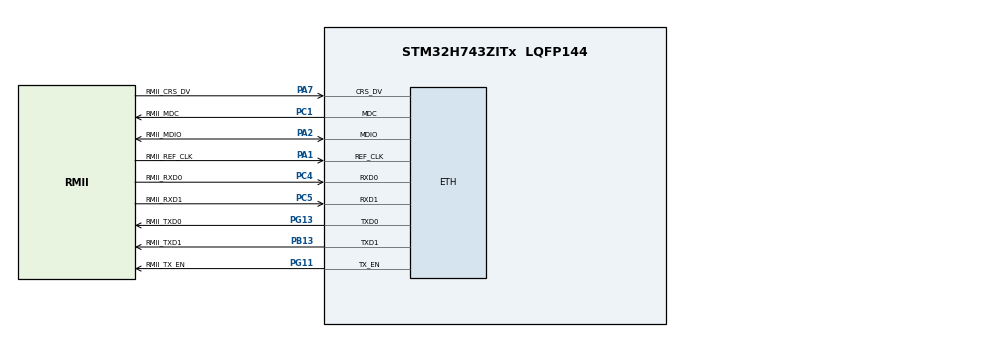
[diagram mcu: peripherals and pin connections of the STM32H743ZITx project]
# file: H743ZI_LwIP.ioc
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CORTEX_M7.AccessPermission-Cortex_Memory_Protection_Unit_Region0_Settings=MPU_REGION_FULL_ACCESS
CORTEX_M7.BaseAddress-Cortex_Memory_Protection_Unit_Region0_Settings=0x30040000
CORTEX_M7.BaseAddress-Cortex_Memory_Protection_Unit_Region1_Settings=0x30044000
CORTEX_M7.CPU_DCache=Enabled
CORTEX_M7.CPU_ICache=Enabled
CORTEX_M7.Enable-Cortex_Memory_Protection_Unit_Region0_Settings=MPU_REGION_ENABLE
CORTEX_M7.Enable-Cortex_Memory_Protection_Unit_Region1_Settings=MPU_REGION_ENABLE
CORTEX_M7.IsBufferable-Cortex_Memory_Protection_Unit_Region0_Settings=MPU_ACCESS_BUFFERABLE
CORTEX_M7.IsCacheable-Cortex_Memory_Protection_Unit_Region1_Settings=MPU_ACCESS_CACHEABLE
CORTEX_M7.MPU_Control=MPU_PRIVILEGED_DEFAULT
CORTEX_M7.Size-Cortex_Memory_Protection_Unit_Region0_Settings=MPU_REGION_SIZE_256B
CORTEX_M7.Size-Cortex_Memory_Protection_Unit_Region1_Settings=MPU_REGION_SIZE_16KB
ETH.MediaInterface=HAL_ETH_RMII_MODE
LWIP.BSP.number=1
LWIP.GATEWAY_ADDRESS=192.168.001.001
LWIP.IP_ADDRESS=192.168.001.100
LWIP.LWIP_DHCP=0
LWIP.NETMASK_ADDRESS=255.255.255.000
LWIP.Version=v2.0.3_Cube
LWIP0.BSP.STBoard=false
LWIP0.BSP.api=BSP_COMPONENT_DRIVER
LWIP0.BSP.component=LAN8742
LWIP0.BSP.i2caddr=0
LWIP0.BSP.instance=LAN8742
LWIP0.BSP.name=Driver_PHY
LWIP0.BSP.solution=LAN8742
Mcu.Family=STM32H7
Mcu.Name=STM32H743ZITx
Mcu.Package=LQFP144
NVIC.PriorityGroup=NVIC_PRIORITYGROUP_4
PA1.GPIO_Label=RMII_REF_CLK
PA1.GPIO_Speed=GPIO_SPEED_FREQ_HIGH
PA1.Mode=RMII
PA1.Signal=ETH_REF_CLK
PA13\ (JTMS/SWDIO).GPIO_Label=TMS
PA13\ (JTMS/SWDIO).Mode=Serial_Wire
PA13\ (JTMS/SWDIO).Signal=SYS_JTMS-SWDIO
PA14\ (JTCK/SWCLK).GPIO_Label=TCK
PA14\ (JTCK/SWCLK).Mode=Serial_Wire
PA14\ (JTCK/SWCLK).Signal=SYS_JTCK-SWCLK
PA2.GPIO_Label=RMII_MDIO
PA2.GPIO_Speed=GPIO_SPEED_FREQ_HIGH
PA2.Mode=RMII
PA2.Signal=ETH_MDIO
PA7.GPIO_Label=RMII_CRS_DV
PA7.GPIO_Speed=GPIO_SPEED_FREQ_HIGH
PA7.Mode=RMII
PA7.Signal=ETH_CRS_DV
PB13.GPIO_Label=RMII_TXD1
PB13.GPIO_Speed=GPIO_SPEED_FREQ_HIGH
PB13.Mode=RMII
PB13.Signal=ETH_TXD1
PC1.GPIO_Label=RMII_MDC
PC1.Mode=RMII
PC1.Signal=ETH_MDC
PC4.GPIO_Label=RMII_RXD0
PC4.GPIO_Speed=GPIO_SPEED_FREQ_HIGH
PC4.Mode=RMII
PC4.Signal=ETH_RXD0
PC5.GPIO_Label=RMII_RXD1
PC5.GPIO_Speed=GPIO_SPEED_FREQ_HIGH
PC5.Mode=RMII
PC5.Signal=ETH_RXD1
PG11.GPIO_Label=RMII_TX_EN
PG11.GPIO_Speed=GPIO_SPEED_FREQ_HIGH
PG11.Mode=RMII
PG11.Signal=ETH_TX_EN
PG13.GPIO_Label=RMII_TXD0
PG13.GPIO_Speed=GPIO_SPEED_FREQ_HIGH
PG13.Mode=RMII
PG13.Signal=ETH_TXD0
PH0-OSC_IN\ (PH0).GPIO_Label=MCO
PH0-OSC_IN\ (PH0).Mode=HSE-External-Oscillator
PH0-OSC_IN\ (PH0).Signal=RCC_OSC_IN
PH1-OSC_OUT\ (PH1).Mode=HSE-External-Oscillator
PH1-OSC_OUT\ (PH1).Signal=RCC_OSC_OUT
ProjectManager.HeapSize=0x2000
ProjectManager.StackSize=0x4000
ProjectManager.TargetToolchain=Makefile
RCC.48MHZClocksFreq_Value=24000000
RCC.ADCFreq_Value=16125000
RCC.AHBFreq_Value=216000000
RCC.APB1CLKDivider=RCC_HCLK_DIV4
RCC.APB1Freq_Value=100000000
RCC.APB1TimFreq_Value=108000000
RCC.APB2CLKDivider=RCC_HCLK_DIV2
RCC.APB2Freq_Value=100000000
RCC.APB2TimFreq_Value=216000000
RCC.APB3Freq_Value=100000000
RCC.APB4Freq_Value=100000000
RCC.CortexFreq_Value=400000000
RCC.D1PPRE=RCC_APB3_DIV2
RCC.D2PPRE1=RCC_APB1_DIV2
RCC.D2PPRE2=RCC_APB2_DIV2
RCC.D3PPRE=RCC_APB4_DIV2
RCC.DIVM1=1
RCC.DIVN1=100
RCC.DIVQ1=4
RCC.HCLKFreq_Value=200000000
RCC.HPRE=RCC_HCLK_DIV2
RCC.HSE_VALUE=8000000
RCC.HSI_VALUE=64000000
RCC.PLLM=25
RCC.PLLMUL=RCC_PLL_MUL9
RCC.PLLN=432
RCC.PLLQ=9
RCC.PLLSourceVirtual=RCC_PLLSOURCE_HSE
RCC.PRESCALERUSB=RCC_USBCLKSOURCE_PLL_DIV1_5
RCC.SYSCLKFreq_VALUE=400000000
RCC.SYSCLKSource=RCC_SYSCLKSOURCE_PLLCLK
RCC.SYSCLKSourceVirtual=RCC_SYSCLKSOURCE_PLLCLK
RCC.USBFreq_Value=200000000
RCC.VCOOutputFreq_Value=432000000
VP_LWIP_VS_Enabled.Mode=Enabled
board=NUCLEO-H743ZI

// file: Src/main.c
/* USER CODE BEGIN Header */
/**
  ******************************************************************************
  * @file           : main.c
  * @brief          : Main program body
  ******************************************************************************
  * This notice applies to any and all portions of this file
  * that are not between comment pairs USER CODE BEGIN and
  * USER CODE END. Other portions of this file, whether
  * inserted by the user or by software development tools
  * are owned by their respective copyright owners.
  *
  * Copyright (c) 2019 STMicroelectronics International N.V.
  * All rights reserved.
  *
  * Redistribution and use in source and binary forms, with or without
  * modification, are permitted, provided that the following conditions are met:
  *
  * 1. Redistribution of source code must retain the above copyright notice,
  *    this list of conditions and the following disclaimer.
  * 2. Redistributions in binary form must reproduce the above copyright notice,
  *    this list of conditions and the following disclaimer in the documentation
  *    and/or other materials provided with the distribution.
  * 3. Neither the name of STMicroelectronics nor the names of other
  *    contributors to this software may be used to endorse or promote products
  *    derived from this software without specific written permission.
  * 4. This software, including modifications and/or derivative works of this
  *    software, must execute solely and exclusively on microcontroller or
  *    microprocessor devices manufactured by or for STMicroelectronics.
  * 5. Redistribution and use of this software other than as permitted under
  *    this license is void and will automatically terminate your rights under
  *    this license.
  *
  * THIS SOFTWARE IS PROVIDED BY STMICROELECTRONICS AND CONTRIBUTORS "AS IS"
  * AND ANY EXPRESS, IMPLIED OR STATUTORY WARRANTIES, INCLUDING, BUT NOT
  * LIMITED TO, THE IMPLIED WARRANTIES OF MERCHANTABILITY, FITNESS FOR A
  * PARTICULAR PURPOSE AND NON-INFRINGEMENT OF THIRD PARTY INTELLECTUAL PROPERTY
  * RIGHTS ARE DISCLAIMED TO THE FULLEST EXTENT PERMITTED BY LAW. IN NO EVENT
  * SHALL STMICROELECTRONICS OR CONTRIBUTORS BE LIABLE FOR ANY DIRECT, INDIRECT,
  * INCIDENTAL, SPECIAL, EXEMPLARY, OR CONSEQUENTIAL DAMAGES (INCLUDING, BUT NOT
  * LIMITED TO, PROCUREMENT OF SUBSTITUTE GOODS OR SERVICES; LOSS OF USE, DATA,
  * OR PROFITS; OR BUSINESS INTERRUPTION) HOWEVER CAUSED AND ON ANY THEORY OF
  * LIABILITY, WHETHER IN CONTRACT, STRICT LIABILITY, OR TORT (INCLUDING
  * NEGLIGENCE OR OTHERWISE) ARISING IN ANY WAY OUT OF THE USE OF THIS SOFTWARE,
  * EVEN IF ADVISED OF THE POSSIBILITY OF SUCH DAMAGE.
  *
  ******************************************************************************
  */
/* USER CODE END Header */

#include "main.h"
#include "lwip.h"

void SystemClock_Config(void);
static void MPU_Config(void);
static void MX_GPIO_Init(void);

int main(void)
{

  /* MPU Configuration--------------------------------------------------------*/
  MPU_Config();

  /* Enable I-Cache---------------------------------------------------------*/
  SCB_EnableICache();

  /* Enable D-Cache---------------------------------------------------------*/
  SCB_EnableDCache();

  /* MCU Configuration--------------------------------------------------------*/

  /* Reset of all peripherals, Initializes the Flash interface and the Systick. */
  HAL_Init();

  /* Configure the system clock */
  SystemClock_Config();

  /* Initialize all configured peripherals */
  MX_GPIO_Init();
  MX_LWIP_Init();

  /* Infinite loop */
  /* USER CODE BEGIN WHILE */
  while (1)
  {
      MX_LWIP_Process();
      HAL_Delay(1);
    /* USER CODE END WHILE */

  }
}

void SystemClock_Config(void)
{
  RCC_OscInitTypeDef RCC_OscInitStruct = {0};
  RCC_ClkInitTypeDef RCC_ClkInitStruct = {0};

  /**Supply configuration update enable
  */
  MODIFY_REG(PWR->CR3, PWR_CR3_SCUEN, 0);
  /**Configure the main internal regulator output voltage
  */
  __HAL_PWR_VOLTAGESCALING_CONFIG(PWR_REGULATOR_VOLTAGE_SCALE1);

  while ((PWR->D3CR & (PWR_D3CR_VOSRDY)) != PWR_D3CR_VOSRDY)
  {

  }
  /**Initializes the CPU, AHB and APB busses clocks
  */
  RCC_OscInitStruct.OscillatorType = RCC_OSCILLATORTYPE_HSE;
  RCC_OscInitStruct.HSEState = RCC_HSE_ON;
  RCC_OscInitStruct.PLL.PLLState = RCC_PLL_ON;
  RCC_OscInitStruct.PLL.PLLSource = RCC_PLLSOURCE_HSE;
  RCC_OscInitStruct.PLL.PLLM = 1;
  RCC_OscInitStruct.PLL.PLLN = 100;
  RCC_OscInitStruct.PLL.PLLP = 2;
  RCC_OscInitStruct.PLL.PLLQ = 4;
  RCC_OscInitStruct.PLL.PLLR = 2;
  RCC_OscInitStruct.PLL.PLLRGE = RCC_PLL1VCIRANGE_3;
  RCC_OscInitStruct.PLL.PLLVCOSEL = RCC_PLL1VCOWIDE;
  RCC_OscInitStruct.PLL.PLLFRACN = 0;
  if (HAL_RCC_OscConfig(&RCC_OscInitStruct) != HAL_OK)
  {
    Error_Handler();
  }
  /**Initializes the CPU, AHB and APB busses clocks
  */
  RCC_ClkInitStruct.ClockType = RCC_CLOCKTYPE_HCLK|RCC_CLOCKTYPE_SYSCLK
                              |RCC_CLOCKTYPE_PCLK1|RCC_CLOCKTYPE_PCLK2
                              |RCC_CLOCKTYPE_D3PCLK1|RCC_CLOCKTYPE_D1PCLK1;
  RCC_ClkInitStruct.SYSCLKSource = RCC_SYSCLKSOURCE_PLLCLK;
  RCC_ClkInitStruct.SYSCLKDivider = RCC_SYSCLK_DIV1;
  RCC_ClkInitStruct.AHBCLKDivider = RCC_HCLK_DIV2;
  RCC_ClkInitStruct.APB3CLKDivider = RCC_APB3_DIV2;
  RCC_ClkInitStruct.APB1CLKDivider = RCC_APB1_DIV2;
  RCC_ClkInitStruct.APB2CLKDivider = RCC_APB2_DIV2;
  RCC_ClkInitStruct.APB4CLKDivider = RCC_APB4_DIV2;

  if (HAL_RCC_ClockConfig(&RCC_ClkInitStruct, FLASH_LATENCY_2) != HAL_OK)
  {
    Error_Handler();
  }
}

static void MX_GPIO_Init(void)
{

  /* GPIO Ports Clock Enable */
  __HAL_RCC_GPIOH_CLK_ENABLE();
  __HAL_RCC_GPIOC_CLK_ENABLE();
  __HAL_RCC_GPIOA_CLK_ENABLE();
  __HAL_RCC_GPIOB_CLK_ENABLE();
  __HAL_RCC_GPIOG_CLK_ENABLE();

}

/* MPU Configuration */

void MPU_Config(void)
{
  MPU_Region_InitTypeDef MPU_InitStruct = {0};

  /* Disables the MPU */
  HAL_MPU_Disable();
  /**Initializes and configures the Region and the memory to be protected
  */
  MPU_InitStruct.Enable = MPU_REGION_ENABLE;
  MPU_InitStruct.Number = MPU_REGION_NUMBER0;
  MPU_InitStruct.BaseAddress = 0x30040000;
  MPU_InitStruct.Size = MPU_REGION_SIZE_256B;
  MPU_InitStruct.SubRegionDisable = 0x0;
  MPU_InitStruct.TypeExtField = MPU_TEX_LEVEL0;
  MPU_InitStruct.AccessPermission = MPU_REGION_FULL_ACCESS;
  MPU_InitStruct.DisableExec = MPU_INSTRUCTION_ACCESS_ENABLE;
  MPU_InitStruct.IsShareable = MPU_ACCESS_NOT_SHAREABLE;
  MPU_InitStruct.IsCacheable = MPU_ACCESS_NOT_CACHEABLE;
  MPU_InitStruct.IsBufferable = MPU_ACCESS_BUFFERABLE;

  HAL_MPU_ConfigRegion(&MPU_InitStruct);
  /**Initializes and configures the Region and the memory to be protected
  */
  MPU_InitStruct.Enable = MPU_REGION_ENABLE;
  MPU_InitStruct.Number = MPU_REGION_NUMBER1;
  MPU_InitStruct.BaseAddress = 0x30044000;
  MPU_InitStruct.Size = MPU_REGION_SIZE_16KB;
  MPU_InitStruct.SubRegionDisable = 0x0;
  MPU_InitStruct.TypeExtField = MPU_TEX_LEVEL0;
  MPU_InitStruct.AccessPermission = MPU_REGION_NO_ACCESS;
  MPU_InitStruct.DisableExec = MPU_INSTRUCTION_ACCESS_ENABLE;
  MPU_InitStruct.IsShareable = MPU_ACCESS_NOT_SHAREABLE;
  MPU_InitStruct.IsCacheable = MPU_ACCESS_CACHEABLE;
  MPU_InitStruct.IsBufferable = MPU_ACCESS_NOT_BUFFERABLE;

  HAL_MPU_ConfigRegion(&MPU_InitStruct);
  /* Enables the MPU */
  HAL_MPU_Enable(MPU_PRIVILEGED_DEFAULT);

}

void Error_Handler(void)
{
}

/************************ (C) COPYRIGHT STMicroelectronics *****END OF FILE****/
